# GD32L235x register map
File version: 1.0
CPU: CM23 r1p0, little endian, no MPU, no FPU, 2 interrupt priority bits
Registers are 32-bit, read-write, reset 0x0 unless marked. A register's access mark holds for its fields unless they carry their own. Offsets are from the block's base; [hi:lo] are bit positions; {n}, {i} and the like mark numbered series.

## FWDGT — free watchdog timer
Base 0x40003000
0x00 CTL wo — Control register
  [15:0] CMD — Key value
0x04 PSC — Prescaler register
  [2:0] PSC — Prescaler divider
0x08 RLD reset 0xFFF — Reload register
  [11:0] RLD — Watchdog counter reload value
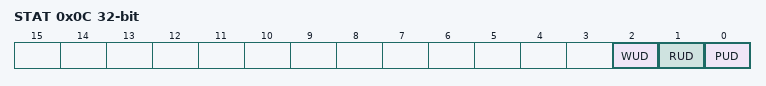
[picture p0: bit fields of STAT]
0x0C STAT ro — Status register
  [2] WUD — Watchdog counter window value update
  [1] RUD — Watchdog counter reload value update
  [0] PUD — Watchdog prescaler value update
0x10 WND reset 0xFFF — Window register
  [11:0] WND — Watchdog counter window value

## GPIOA — General-purpose I/Os
Base 0x48000000
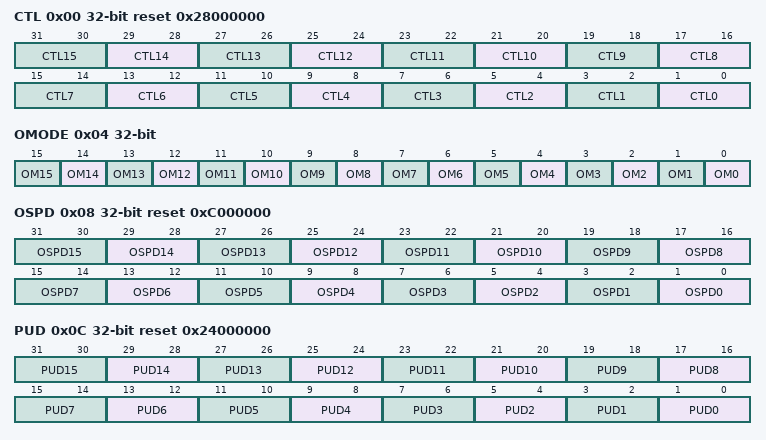
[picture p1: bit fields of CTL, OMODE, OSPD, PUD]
0x00 CTL reset 0x28000000 — GPIO port control register
  [2n+1:2n] CTL{n} (n=0..15) — Port x configuration bits (y = 0..15)
0x04 OMODE — GPIO port output type register
  [n] OM{n} (n=0..15) — Port x configuration bit {n}
0x08 OSPD reset 0xC000000 — GPIO port output speed register
  [2n+1:2n] OSPD{n} (n=0..15) — Port x configuration bits (y = 0..15)
0x0C PUD reset 0x24000000 — GPIO port pull-up/pull-down register
  [2n+1:2n] PUD{n} (n=0..15) — Port x configuration bits (y = 0..15)
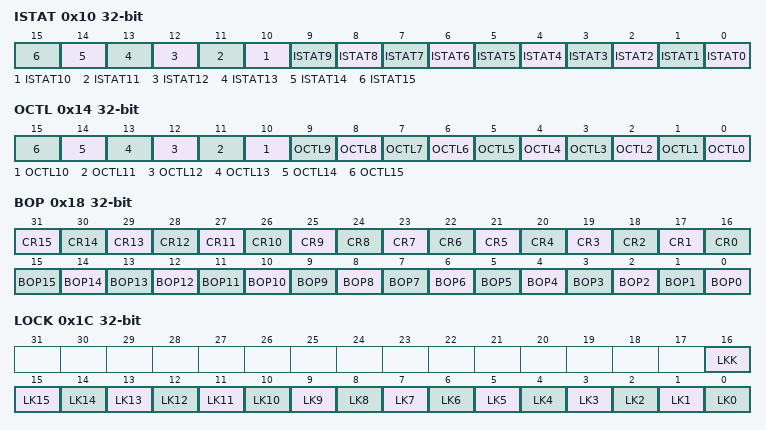
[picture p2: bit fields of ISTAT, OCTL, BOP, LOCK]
0x10 ISTAT ro — GPIO port input data register
  [n] ISTAT{n} (n=0..15) — Port input data (y = 0..15)
0x14 OCTL — GPIO port output data register
  [n] OCTL{n} (n=0..15) — Port output data (y = 0..15)
0x18 BOP wo — GPIO port bit set/reset register
  [n+16] CR{n} (n=1..15) — Port x reset bit y (y = 0..15)
  [16] CR0 — Port x reset bit y (y= 0..15)
  [n] BOP{n} (n=0..15) — Port x set bit y (y= 0..15)
0x1C LOCK — GPIO port configuration lock register
  [16] LKK — Port x lock bit y
  [n] LK{n} (n=0..15) — Port x lock bit y (y= 0..15)
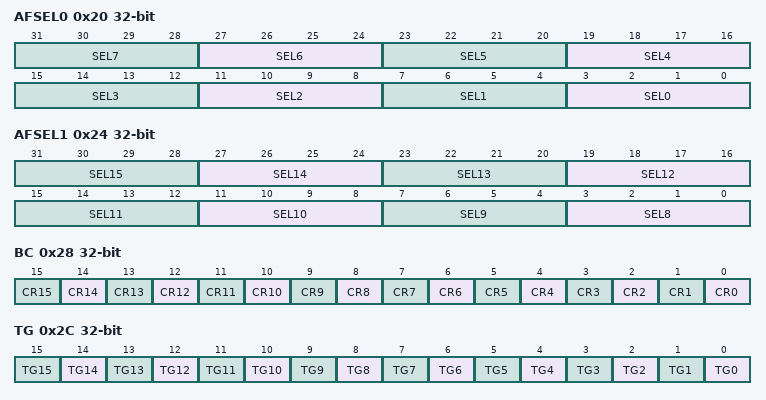
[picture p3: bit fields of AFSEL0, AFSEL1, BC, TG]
0x20 AFSEL0 — GPIO alternate function low register
  [4n+3:4n] SEL{n} (n=0..7) — Alternate function selection for port x bit y (y = 0..7)
0x24 AFSEL1 — GPIO alternate function register 1
  [4n-29:4n-32] SEL{n} (n=8..15) — Alternate function selection for port x bit y (y = 8..15)
0x28 BC wo — Port bit reset register
  [n] CR{n} (n=0..15) — Port cleat bit
0x2C TG wo — Port bit toggle register
  [n] TG{n} (n=0..15) — Port toggle bit

## GPIOB — General-purpose I/Os
Base 0x48000400
Registers as GPIOA; these are added or differ:
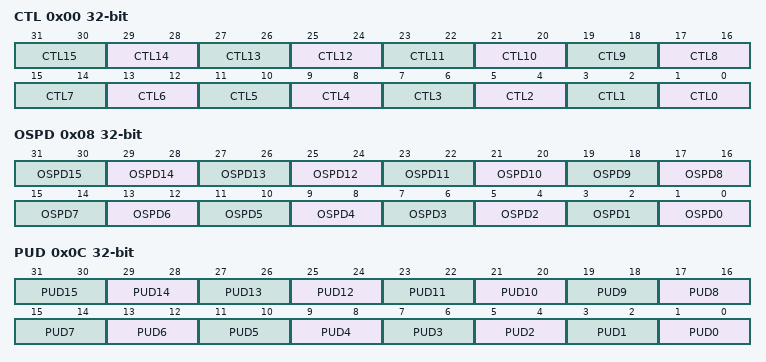
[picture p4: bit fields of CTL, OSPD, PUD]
0x00 CTL — GPIO port control register
  [2n+1:2n] CTL{n} (n=0..15) — Port x configuration bits (y = 0..15)
0x08 OSPD — GPIO port output speed register
  [2n+1:2n] OSPD{n} (n=0..15) — Port x configuration bits (y = 0..15)
0x0C PUD — GPIO port pull-up/pull-down register
  [2n+1:2n] PUD{n} (n=0..15) — Port x configuration bits (y = 0..15)

## GPIOC — General-purpose I/Os
Base 0x48000800
Registers as GPIOB, without LOCK.

## GPIOD — General-purpose I/Os
Base 0x48000C00
Registers as GPIOB, without LOCK.

## GPIOF — General-purpose I/Os
Base 0x48001400
Registers as GPIOB, without LOCK, AFSEL0, AFSEL1; these are added or differ:
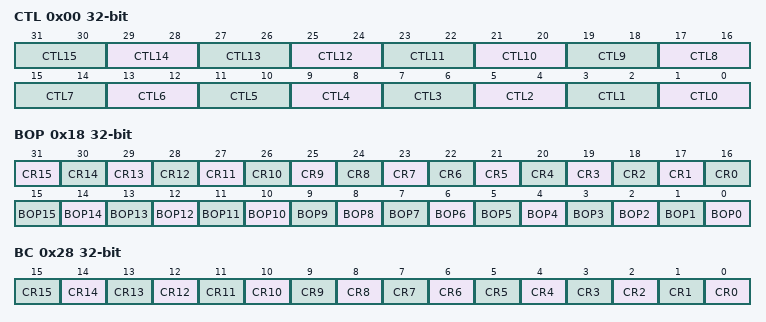
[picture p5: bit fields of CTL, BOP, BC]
0x00 CTL — GPIOF port control register
  [2n+1:2n] CTL{n} (n=0..15) — Port x configuration bits (y = 0..15)
0x18 BOP wo — GPIO port bit set/reset register
  [n+16] CR{n} (n=1..15) — Port x reset bit y (y = 0..15)
  [16] CR0 — Port x set bit y (y= 0..15)
  [n] BOP{n} (n=0..15) — Port x set bit y (y= 0..15)
0x28 BC wo — Port bit reset register
  [n] CR{n} (n=0..15) — Port x Reset bit y

## LPTIMER0 — Low power timers
Base 0x40009400
Same registers: LPTIMER1 0x40007C00
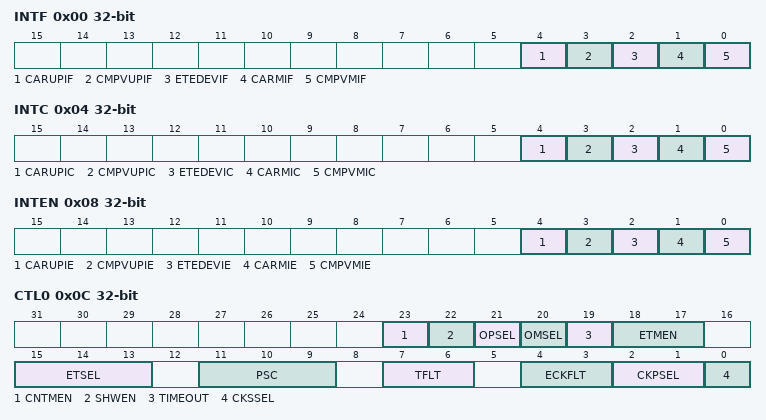
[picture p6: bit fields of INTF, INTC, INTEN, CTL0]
0x00 INTF ro — Interrupt flag register
  [4] CARUPIF — Counter auto reload register update interrupt flag
  [3] CMPVUPIF — Compare value register update interrupt flag
  [2] ETEDEVIF — External trigger edge event interrupt flag
  [1] CARMIF — Counter auto reload register match interrupt flag
  [0] CMPVMIF — Compare value register match interrupt flag
0x04 INTC — Interrupt flag clear register
  [4] CARUPIC — Counter auto reload register update interrupt flag clear
  [3] CMPVUPIC — Compare value register update interrupt flag clear
  [2] ETEDEVIC — External trigger edge event interrupt flag clear
  [1] CARMIC — Counter auto reload register match interrupt flag clear
  [0] CMPVMIC — Compare value register match interrupt flag clear
0x08 INTEN — Interrupt enable register
  [4] CARUPIE — Counter auto reload register update interrupt
  [3] CMPVUPIE — Compare value register update interrupt
  [2] ETEDEVIE — External trigger edge event interrupt
  [1] CARMIE — Counter auto reload register match interrupt
  [0] CMPVMIE — Compare value register match interrupt
0x0C CTL0 — Control register 0
  [23] CNTMEN — Counter mode select
  [22] SHWEN — LPTIMER_CAR and LPTIMER_CMPV shadow registers enable
  [21] OPSEL — Output polarity select
  [20] OMSEL — Output Mode select
  [19] TIMEOUT — Timeout enable
  [18:17] ETMEN — External Trigger mode enable
  [15:13] ETSEL — External trigger select
  [11:9] PSC — Clock prescaler selection
  [7:6] TFLT — Trigger filter
  [4:3] ECKFLT — External clock filter
  [2:1] CKPSEL — Clock polarity select
  [0] CKSSEL — Clock source select
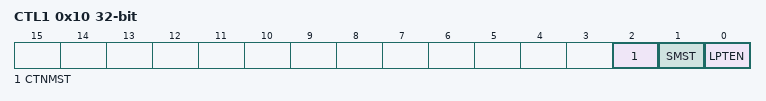
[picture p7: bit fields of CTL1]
0x10 CTL1 — Control register 1
  [2] CTNMST — LPTIMER start in continus counting mode.
  [1] SMST — LPTIMER start in single counting mode
  [0] LPTEN — LPTIMER enable
0x14 CMPV — Compare value register
  [15:0] CMPVAL — Compare value
0x18 CAR — Counter auto reload value
  [15:0] CARL — Low Auto-reload value
0x1C CNT — counter register
  [15:0] CNT — Low counter value
0x20 EIRMP — External input remap register
  [1:0] EI_RMP — External input remap 1
